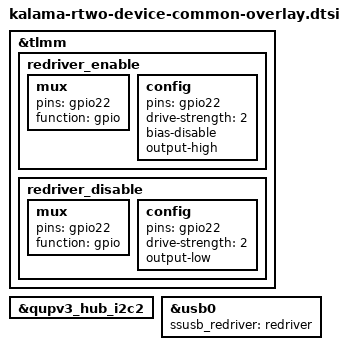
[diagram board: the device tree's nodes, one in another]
/* Copyright (c) 2021, The Linux Foundation. All rights reserved.
 *
 * This program is free software; you can redistribute it and/or modify
 * it under the terms of the GNU General Public License version 2 and
 * only version 2 as published by the Free Software Foundation.
 *
 * This program is distributed in the hope that it will be useful,
 * but WITHOUT ANY WARRANTY; without even the implied warranty of
 * MERCHANTABILITY or FITNESS FOR A PARTICULAR PURPOSE.  See the
 * GNU General Public License for more details.
 */

/* This file is only for rtwo device */

#include "kalama-rtwo-products-common-overlay.dtsi"
#include "kalama-moto-common-charger.dtsi"

&tlmm {
	redriver_enable: redriver_enable {
		mux {
			pins = "gpio22";
			function = "gpio";
		};

		config {
			pins = "gpio22";
			drive-strength = <2>;
			bias-disable; /* NO PULL */
			output-high;
		};
	};
	redriver_disable: redriver_disable {
		mux {
			pins = "gpio22";
			function = "gpio";
		};

		config {
			pins = "gpio22";
			drive-strength = <2>;
			output-low;
		};
	};
};

&qupv3_hub_i2c2 {
	status = "ok";
	#include "kalama-moto-common-redriver.dtsi"
};

&usb0 {
	ssusb_redriver = <&redriver>;
};
